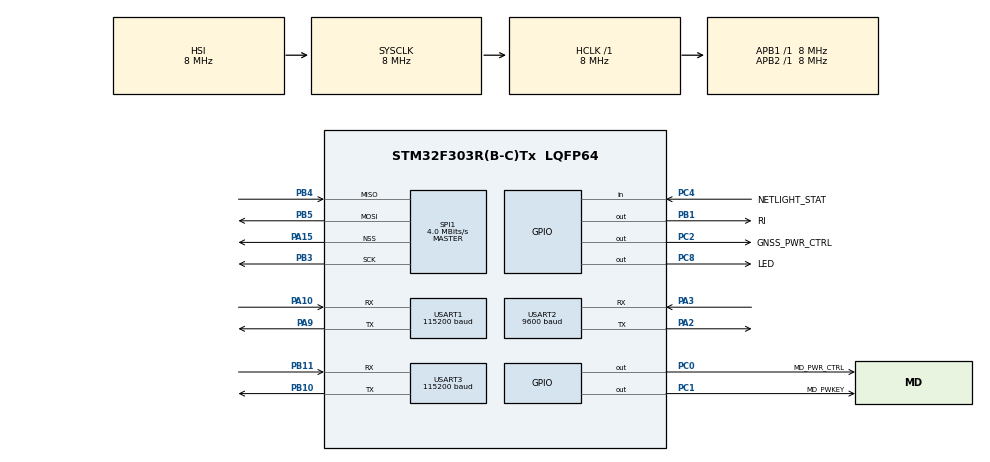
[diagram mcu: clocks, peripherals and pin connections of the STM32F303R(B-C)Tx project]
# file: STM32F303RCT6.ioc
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Dma.Request0=USART1_RX
Dma.Request1=USART3_RX
Dma.USART1_RX.0.Direction=DMA_PERIPH_TO_MEMORY
Dma.USART1_RX.0.Instance=DMA1_Channel5
Dma.USART1_RX.0.MemDataAlignment=DMA_MDATAALIGN_BYTE
Dma.USART1_RX.0.MemInc=DMA_MINC_ENABLE
Dma.USART1_RX.0.Mode=DMA_NORMAL
Dma.USART1_RX.0.PeriphDataAlignment=DMA_PDATAALIGN_BYTE
Dma.USART1_RX.0.PeriphInc=DMA_PINC_DISABLE
Dma.USART1_RX.0.Priority=DMA_PRIORITY_LOW
Dma.USART3_RX.1.Direction=DMA_PERIPH_TO_MEMORY
Dma.USART3_RX.1.Instance=DMA1_Channel3
Dma.USART3_RX.1.MemDataAlignment=DMA_MDATAALIGN_BYTE
Dma.USART3_RX.1.MemInc=DMA_MINC_ENABLE
Dma.USART3_RX.1.Mode=DMA_NORMAL
Dma.USART3_RX.1.PeriphDataAlignment=DMA_PDATAALIGN_BYTE
Dma.USART3_RX.1.PeriphInc=DMA_PINC_DISABLE
Dma.USART3_RX.1.Priority=DMA_PRIORITY_LOW
FREERTOS.Tasks01=defaultTask,0,128,StartDefaultTask,Default,NULL,Dynamic,NULL,NULL
FREERTOS.configTOTAL_HEAP_SIZE=5120
Mcu.Family=STM32F3
Mcu.Name=STM32F303R(B-C)Tx
Mcu.Package=LQFP64
NVIC.DMA1_Channel3_IRQn=true\:5\:0\:false\:false\:true\:true\:false\:true\:true
NVIC.DMA1_Channel5_IRQn=true\:5\:0\:false\:false\:true\:true\:false\:true\:true
NVIC.PriorityGroup=NVIC_PRIORITYGROUP_4
NVIC.SPI1_IRQn=true\:5\:0\:false\:false\:true\:true\:true\:true\:true
NVIC.TIM1_UP_TIM16_IRQn=true\:15\:0\:false\:false\:true\:false\:false\:true\:true
NVIC.TimeBase=TIM1_UP_TIM16_IRQn
NVIC.TimeBaseIP=TIM1
NVIC.USART1_IRQn=true\:5\:0\:false\:false\:true\:true\:true\:true\:true
NVIC.USART2_IRQn=true\:5\:0\:false\:false\:true\:true\:true\:true\:true
NVIC.USART3_IRQn=true\:5\:0\:false\:false\:true\:true\:true\:true\:true
PA10.Mode=Asynchronous
PA10.Signal=USART1_RX
PA15.Mode=NSS_Signal_Hard_Output
PA15.Signal=SPI1_NSS
PA2.Mode=Asynchronous
PA2.Signal=USART2_TX
PA3.Mode=Asynchronous
PA3.Signal=USART2_RX
PA9.Mode=Asynchronous
PA9.Signal=USART1_TX
PB1.GPIO_Label=RI
PB1.Signal=GPIO_Output
PB10.Mode=Asynchronous
PB10.Signal=USART3_TX
PB11.Mode=Asynchronous
PB11.Signal=USART3_RX
PB3.Mode=Full_Duplex_Master
PB3.Signal=SPI1_SCK
PB4.Mode=Full_Duplex_Master
PB4.Signal=SPI1_MISO
PB5.Mode=Full_Duplex_Master
PB5.Signal=SPI1_MOSI
PC0.GPIO_Label=MD_PWR_CTRL
PC0.Signal=GPIO_Output
PC1.GPIO_Label=MD_PWKEY
PC1.Signal=GPIO_Output
PC2.GPIO_Label=GNSS_PWR_CTRL
PC2.Signal=GPIO_Output
PC4.GPIO_Label=NETLIGHT_STAT
PC4.Signal=GPIO_Input
PC8.GPIO_Label=LED
PC8.Signal=GPIO_Output
ProjectManager.HeapSize=0x200
ProjectManager.StackSize=0x400
ProjectManager.TargetToolchain=MDK-ARM V5.32
RCC.AHBFreq_Value=8000000
RCC.APB1Freq_Value=8000000
RCC.APB2Freq_Value=8000000
RCC.CortexFreq_Value=8000000
RCC.HSE_VALUE=8000000
RCC.HSI_VALUE=8000000
RCC.LSE_VALUE=32768
RCC.SYSCLKFreq_VALUE=8000000
SPI1.CLKPhase=SPI_PHASE_2EDGE
SPI1.CLKPolarity=SPI_POLARITY_HIGH
SPI1.CalculateBaudRate=4.0 MBits/s
SPI1.DataSize=SPI_DATASIZE_8BIT
SPI1.Direction=SPI_DIRECTION_2LINES
SPI1.Mode=SPI_MODE_MASTER
SPI1.VirtualNSS=VM_NSSHARD
SPI1.VirtualType=VM_MASTER
USART1.BaudRate=115200
USART1.VirtualMode-Asynchronous=VM_ASYNC
USART2.BaudRate=9600
USART2.VirtualMode-Asynchronous=VM_ASYNC
USART3.BaudRate=115200
USART3.VirtualMode-Asynchronous=VM_ASYNC
VP_FREERTOS_VS_CMSIS_V1.Mode=CMSIS_V1
VP_SYS_VS_tim1.Mode=TIM1
board=custom

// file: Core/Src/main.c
/* USER CODE BEGIN Header */
/**
  ******************************************************************************
  * @file           : main.c
  * @brief          : Main program body
  ******************************************************************************
  * @attention
  *
  * Copyright (c) 2025 STMicroelectronics.
  * All rights reserved.
  *
  * This software is licensed under terms that can be found in the LICENSE file
  * in the root directory of this software component.
  * If no LICENSE file comes with this software, it is provided AS-IS.
  *
  ******************************************************************************
  */
/* USER CODE END Header */
#include "main.h"
#include "cmsis_os.h"

/* USER CODE BEGIN Includes */
#include "Blynk_Task.h"
#include "UART_Task.h"
#include "Flash_Task.h"
#include "GPS_GNSS.h"
#include "ModuleEC600.h"
#include "HAL_UART_Callback.h"
/* USER CODE END Includes */

SPI_HandleTypeDef hspi1;

UART_HandleTypeDef huart1;
UART_HandleTypeDef huart2;
UART_HandleTypeDef huart3;
DMA_HandleTypeDef hdma_usart1_rx;
DMA_HandleTypeDef hdma_usart3_rx;

osThreadId defaultTaskHandle;

void SystemClock_Config(void);
static void MX_GPIO_Init(void);
static void MX_DMA_Init(void);
static void MX_USART1_UART_Init(void);
static void MX_SPI1_Init(void);
static void MX_USART2_UART_Init(void);
static void MX_USART3_UART_Init(void);
void StartDefaultTask(void const * argument);

int main(void)
{

  /* MCU Configuration--------------------------------------------------------*/

  /* Reset of all peripherals, Initializes the Flash interface and the Systick. */
  HAL_Init();

  /* Configure the system clock */
  SystemClock_Config();

  /* Initialize all configured peripherals */
  MX_GPIO_Init();
  MX_DMA_Init();
  MX_USART1_UART_Init();
  MX_SPI1_Init();
  MX_USART2_UART_Init();
  MX_USART3_UART_Init();

  /* Create the thread(s) */
  /* definition and creation of defaultTask */
  osThreadDef(defaultTask, StartDefaultTask, osPriorityNormal, 0, 128);
  defaultTaskHandle = osThreadCreate(osThread(defaultTask), NULL);

  /* USER CODE BEGIN RTOS_THREADS */
  CreateBlynkTask();
  CreateUARTTask();
  CreateFlashTask();
  CreateGPSTask();
  CreateEC600Task();
  /* USER CODE END RTOS_THREADS */

  /* Start scheduler */
  osKernelStart();

  /* We should never get here as control is now taken by the scheduler */

  /* Infinite loop */
  while (1)
  {

  }
}

void SystemClock_Config(void)
{
  RCC_OscInitTypeDef RCC_OscInitStruct = {0};
  RCC_ClkInitTypeDef RCC_ClkInitStruct = {0};
  RCC_PeriphCLKInitTypeDef PeriphClkInit = {0};

  /** Initializes the RCC Oscillators according to the specified parameters
  * in the RCC_OscInitTypeDef structure.
  */
  RCC_OscInitStruct.OscillatorType = RCC_OSCILLATORTYPE_HSI;
  RCC_OscInitStruct.HSIState = RCC_HSI_ON;
  RCC_OscInitStruct.HSICalibrationValue = RCC_HSICALIBRATION_DEFAULT;
  RCC_OscInitStruct.PLL.PLLState = RCC_PLL_NONE;
  if (HAL_RCC_OscConfig(&RCC_OscInitStruct) != HAL_OK)
  {
    Error_Handler();
  }

  /** Initializes the CPU, AHB and APB buses clocks
  */
  RCC_ClkInitStruct.ClockType = RCC_CLOCKTYPE_HCLK|RCC_CLOCKTYPE_SYSCLK
                              |RCC_CLOCKTYPE_PCLK1|RCC_CLOCKTYPE_PCLK2;
  RCC_ClkInitStruct.SYSCLKSource = RCC_SYSCLKSOURCE_HSI;
  RCC_ClkInitStruct.AHBCLKDivider = RCC_SYSCLK_DIV1;
  RCC_ClkInitStruct.APB1CLKDivider = RCC_HCLK_DIV1;
  RCC_ClkInitStruct.APB2CLKDivider = RCC_HCLK_DIV1;

  if (HAL_RCC_ClockConfig(&RCC_ClkInitStruct, FLASH_LATENCY_0) != HAL_OK)
  {
    Error_Handler();
  }
  PeriphClkInit.PeriphClockSelection = RCC_PERIPHCLK_USART1|RCC_PERIPHCLK_USART2
                              |RCC_PERIPHCLK_USART3;
  PeriphClkInit.Usart1ClockSelection = RCC_USART1CLKSOURCE_PCLK2;
  PeriphClkInit.Usart2ClockSelection = RCC_USART2CLKSOURCE_PCLK1;
  PeriphClkInit.Usart3ClockSelection = RCC_USART3CLKSOURCE_PCLK1;
  if (HAL_RCCEx_PeriphCLKConfig(&PeriphClkInit) != HAL_OK)
  {
    Error_Handler();
  }
}

static void MX_SPI1_Init(void)
{

  /* SPI1 parameter configuration*/
  hspi1.Instance = SPI1;
  hspi1.Init.Mode = SPI_MODE_MASTER;
  hspi1.Init.Direction = SPI_DIRECTION_2LINES;
  hspi1.Init.DataSize = SPI_DATASIZE_8BIT;
  hspi1.Init.CLKPolarity = SPI_POLARITY_HIGH;
  hspi1.Init.CLKPhase = SPI_PHASE_2EDGE;
  hspi1.Init.NSS = SPI_NSS_HARD_OUTPUT;
  hspi1.Init.BaudRatePrescaler = SPI_BAUDRATEPRESCALER_2;
  hspi1.Init.FirstBit = SPI_FIRSTBIT_MSB;
  hspi1.Init.TIMode = SPI_TIMODE_DISABLE;
  hspi1.Init.CRCCalculation = SPI_CRCCALCULATION_DISABLE;
  hspi1.Init.CRCPolynomial = 7;
  hspi1.Init.CRCLength = SPI_CRC_LENGTH_DATASIZE;
  hspi1.Init.NSSPMode = SPI_NSS_PULSE_DISABLE;
  if (HAL_SPI_Init(&hspi1) != HAL_OK)
  {
    Error_Handler();
  }

}

static void MX_USART1_UART_Init(void)
{

  huart1.Instance = USART1;
  huart1.Init.BaudRate = 115200;
  huart1.Init.WordLength = UART_WORDLENGTH_8B;
  huart1.Init.StopBits = UART_STOPBITS_1;
  huart1.Init.Parity = UART_PARITY_NONE;
  huart1.Init.Mode = UART_MODE_TX_RX;
  huart1.Init.HwFlowCtl = UART_HWCONTROL_NONE;
  huart1.Init.OverSampling = UART_OVERSAMPLING_16;
  huart1.Init.OneBitSampling = UART_ONE_BIT_SAMPLE_DISABLE;
  huart1.AdvancedInit.AdvFeatureInit = UART_ADVFEATURE_NO_INIT;
  if (HAL_UART_Init(&huart1) != HAL_OK)
  {
    Error_Handler();
  }

}

static void MX_USART2_UART_Init(void)
{

  huart2.Instance = USART2;
  huart2.Init.BaudRate = 9600;
  huart2.Init.WordLength = UART_WORDLENGTH_8B;
  huart2.Init.StopBits = UART_STOPBITS_1;
  huart2.Init.Parity = UART_PARITY_NONE;
  huart2.Init.Mode = UART_MODE_TX_RX;
  huart2.Init.HwFlowCtl = UART_HWCONTROL_NONE;
  huart2.Init.OverSampling = UART_OVERSAMPLING_16;
  huart2.Init.OneBitSampling = UART_ONE_BIT_SAMPLE_DISABLE;
  huart2.AdvancedInit.AdvFeatureInit = UART_ADVFEATURE_NO_INIT;
  if (HAL_UART_Init(&huart2) != HAL_OK)
  {
    Error_Handler();
  }

}

static void MX_USART3_UART_Init(void)
{

  huart3.Instance = USART3;
  huart3.Init.BaudRate = 115200;
  huart3.Init.WordLength = UART_WORDLENGTH_8B;
  huart3.Init.StopBits = UART_STOPBITS_1;
  huart3.Init.Parity = UART_PARITY_NONE;
  huart3.Init.Mode = UART_MODE_TX_RX;
  huart3.Init.HwFlowCtl = UART_HWCONTROL_NONE;
  huart3.Init.OverSampling = UART_OVERSAMPLING_16;
  huart3.Init.OneBitSampling = UART_ONE_BIT_SAMPLE_DISABLE;
  huart3.AdvancedInit.AdvFeatureInit = UART_ADVFEATURE_NO_INIT;
  if (HAL_UART_Init(&huart3) != HAL_OK)
  {
    Error_Handler();
  }

}

static void MX_DMA_Init(void)
{

  /* DMA controller clock enable */
  __HAL_RCC_DMA1_CLK_ENABLE();

  /* DMA interrupt init */
  /* DMA1_Channel3_IRQn interrupt configuration */
  HAL_NVIC_SetPriority(DMA1_Channel3_IRQn, 5, 0);
  HAL_NVIC_EnableIRQ(DMA1_Channel3_IRQn);
  /* DMA1_Channel5_IRQn interrupt configuration */
  HAL_NVIC_SetPriority(DMA1_Channel5_IRQn, 5, 0);
  HAL_NVIC_EnableIRQ(DMA1_Channel5_IRQn);

}

static void MX_GPIO_Init(void)
{
  GPIO_InitTypeDef GPIO_InitStruct = {0};

  /* GPIO Ports Clock Enable */
  __HAL_RCC_GPIOC_CLK_ENABLE();
  __HAL_RCC_GPIOA_CLK_ENABLE();
  __HAL_RCC_GPIOB_CLK_ENABLE();

  /*Configure GPIO pin Output Level */
  HAL_GPIO_WritePin(GPIOC, MD_PWR_CTRL_Pin|MD_PWKEY_Pin|GNSS_PWR_CTRL_Pin|LED_Pin, GPIO_PIN_RESET);

  /*Configure GPIO pin Output Level */
  HAL_GPIO_WritePin(RI_GPIO_Port, RI_Pin, GPIO_PIN_RESET);

  /*Configure GPIO pins : MD_PWR_CTRL_Pin MD_PWKEY_Pin GNSS_PWR_CTRL_Pin LED_Pin */
  GPIO_InitStruct.Pin = MD_PWR_CTRL_Pin|MD_PWKEY_Pin|GNSS_PWR_CTRL_Pin|LED_Pin;
  GPIO_InitStruct.Mode = GPIO_MODE_OUTPUT_PP;
  GPIO_InitStruct.Pull = GPIO_NOPULL;
  GPIO_InitStruct.Speed = GPIO_SPEED_FREQ_LOW;
  HAL_GPIO_Init(GPIOC, &GPIO_InitStruct);

  /*Configure GPIO pin : NETLIGHT_STAT_Pin */
  GPIO_InitStruct.Pin = NETLIGHT_STAT_Pin;
  GPIO_InitStruct.Mode = GPIO_MODE_INPUT;
  GPIO_InitStruct.Pull = GPIO_NOPULL;
  HAL_GPIO_Init(NETLIGHT_STAT_GPIO_Port, &GPIO_InitStruct);

  /*Configure GPIO pin : RI_Pin */
  GPIO_InitStruct.Pin = RI_Pin;
  GPIO_InitStruct.Mode = GPIO_MODE_OUTPUT_PP;
  GPIO_InitStruct.Pull = GPIO_NOPULL;
  GPIO_InitStruct.Speed = GPIO_SPEED_FREQ_LOW;
  HAL_GPIO_Init(RI_GPIO_Port, &GPIO_InitStruct);

}

void StartDefaultTask(void const * argument)
{
  /* USER CODE BEGIN 5 */
	uint8_t mess[] = "Start!!!!\r\n";
	HAL_UART_Transmit(&huart1, mess, sizeof(mess) - 1, 1000);
  /* Infinite loop */
  for(;;)
  {
    osDelay(1);
  }
  /* USER CODE END 5 */
}

void HAL_TIM_PeriodElapsedCallback(TIM_HandleTypeDef *htim)
{
  if (htim->Instance == TIM1) {
    HAL_IncTick();
  }
}

void Error_Handler(void)
{
  __disable_irq();
  while (1)
  {
  }
}
